# PIC32CX5112MTSH128S1 device description
Architecture: CORTEX-M4; Family: PIC32CXMT; Series: PIC32CXMTSH
Registers are 32-bit, read-write, no defined reset value unless marked. A register's access mark holds for its fields unless they carry their own. Offsets are from the block's base; [hi:lo] are bit positions; {n}, {i} and the like mark numbered series; <NAME> marks a mode.

## ADC — Analog-to-Digital Converter
Instances: ADC 0x40024000
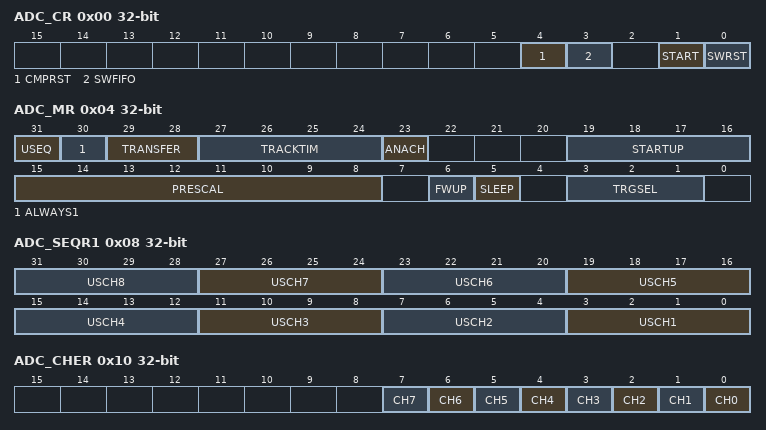
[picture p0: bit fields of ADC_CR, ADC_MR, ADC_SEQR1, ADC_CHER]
0x00 ADC_CR wo — Control Register
  [4] CMPRST — Comparison Restart
  [3] SWFIFO — Software FIFO Reset
  [1] START — Start Conversion
  [0] SWRST — Software Reset
0x04 ADC_MR — Mode Register
  [31] USEQ — User Sequence Enable
    0=NUM_ORDER (Normal mode: The controller converts channels in a simple numeric order depending only on the channel index.); 1=REG_ORDER (User Sequence mode: The sequence respects what is defined in ADC_SEQR1and can be used to convert the same channel several times.)
  [30] ALWAYS1
  [29:28] TRANSFER — Transfer Time
  [27:24] TRACKTIM — Tracking Time
  [23] ANACH — Analog Change
    0=NONE (No analog change on channel switching: DIFF0 is used for all channels.); 1=ALLOWED (Allows different analog settings for each channel. See ADC Channel Configuration Register.)
  [19:16] STARTUP — Startup Time
    0=SUT0 (0 period of ADCCLK); 1=SUT8 (8 periods of ADCCLK); 2=SUT16 (16 periods of ADCCLK); 3=SUT24 (24 periods of ADCCLK); 4=SUT64 (64 periods of ADCCLK); 5=SUT80 (80 periods of ADCCLK); 6=SUT96 (96 periods of ADCCLK); 7=SUT112 (112 periods of ADCCLK); 8=SUT512 (512 periods of ADCCLK); 9=SUT576 (576 periods of ADCCLK); 10=SUT640 (640 periods of ADCCLK); 11=SUT704 (704 periods of ADCCLK); 12=SUT768 (768 periods of ADCCLK); 13=SUT832 (832 periods of ADCCLK); 14=SUT896 (896 periods of ADCCLK); 15=SUT960 (960 periods of ADCCLK)
  [15:8] PRESCAL — Prescaler Rate Selection
  [6] FWUP — Fast Wake-up
    0=OFF (If SLEEP is 1, then both ADC core and reference voltage circuitry are off between conversions.); 1=ON (If SLEEP is 1, then Fast Wake-up Sleep mode: The voltage reference is on between conversions and ADC core is off.)
  [5] SLEEP — Sleep Mode
    0=NORMAL (Normal mode: The ADC core and reference voltage circuitry are kept on between conversions.); 1=SLEEP (Sleep mode: The wake-up time can be modified by programming the FWUP bit.)
  [3:1] TRGSEL — Trigger Selection
    0=ADC_TRIG0 (PWM event line 0); 1=ADC_TRIG1 (TIOA0 TC0); 2=ADC_TRIG2 (TIOA1 TC0); 3=ADC_TRIG3 (TIOA2 TC0); 4=ADC_TRIG4 (TIOA0 TC1); 5=ADC_TRIG5 (TIOA1 TC1); 6=ADC_TRIG6 (RTCOUT0)
0x08 ADC_SEQR1 — Channel Sequence Register 1
  [4n-1:4n-4] USCH{n} (n=1..8) — User Sequence Number {n}
0x10 ADC_CHER wo — Channel Enable Register
  [n] CH{n} (n=0..7) — Channel {n} Enable
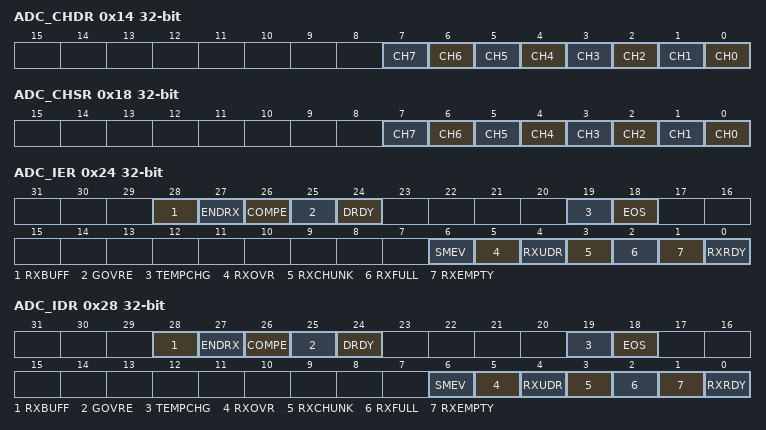
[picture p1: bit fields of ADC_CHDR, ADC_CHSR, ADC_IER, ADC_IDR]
0x14 ADC_CHDR wo — Channel Disable Register
  [n] CH{n} (n=0..7) — Channel {n} Disable
0x18 ADC_CHSR ro — Channel Status Register
  [n] CH{n} (n=0..7) — Channel {n} Status
0x20 ADC_LCDR ro — Last Converted Data Register
  [28:24] CHNBOSR <DEFAULT> — Channel Number in Oversampling Mode
  [15:0] LDATA <DEFAULT> — Last Data Converted
  [15:12] NO_OSR_CHNB <NO_OSR> — Channel Number when No Oversampling
  [11:0] NO_OSR_LDATA <NO_OSR> — Last Data Converted when No Oversampling
0x24 ADC_IER wo — Interrupt Enable Register
  [28] RXBUFF — Receive Buffer Full Interrupt Enable
  [27] ENDRX — End of Receive Transfer Interrupt Enable
  [26] COMPE — Comparison Event Interrupt Enable
  [25] GOVRE — General Overrun Error Interrupt Enable
  [24] DRDY — Data Ready Interrupt Enable
  [19] TEMPCHG — Temperature Change Interrupt Enable
  [18] EOS — End Of Sequence Interrupt Enable
  [6] SMEV — Supply Monitor Event Interrupt Enable
  [5] RXOVR — Receive Over Flow Interrupt Enable
  [4] RXUDR — Receive Under Flow Interrupt Enable
  [3] RXCHUNK — Receive FIFO Chunk Interrupt Enable
  [2] RXFULL — Receive FIFO Full Interrupt Enable
  [1] RXEMPTY — Receive FIFO Empty Interrupt Enable
  [0] RXRDY — Receive Ready Interrupt Enable
0x28 ADC_IDR wo — Interrupt Disable Register
  [28] RXBUFF — Receive Buffer Full Interrupt Disable
  [27] ENDRX — End of Receive Transfer Interrupt Disable
  [26] COMPE — Comparison Event Interrupt Disable
  [25] GOVRE — General Overrun Error Interrupt Disable
  [24] DRDY — Data Ready Interrupt Disable
  [19] TEMPCHG — Temperature Change Interrupt Disable
  [18] EOS — End Of Sequence Interrupt Disable
  [6] SMEV — Supply Monitor Event Interrupt Disable
  [5] RXOVR — Receive Over Flow Interrupt Disable
  [4] RXUDR — Receive Under Flow Interrupt Disable
  [3] RXCHUNK — Receive FIFO Chunk Interrupt Disable
  [2] RXFULL — Receive FIFO Full Interrupt Disable
  [1] RXEMPTY — Receive FIFO Empty Interrupt Disable
  [0] RXRDY — Receive Ready Interrupt Disable
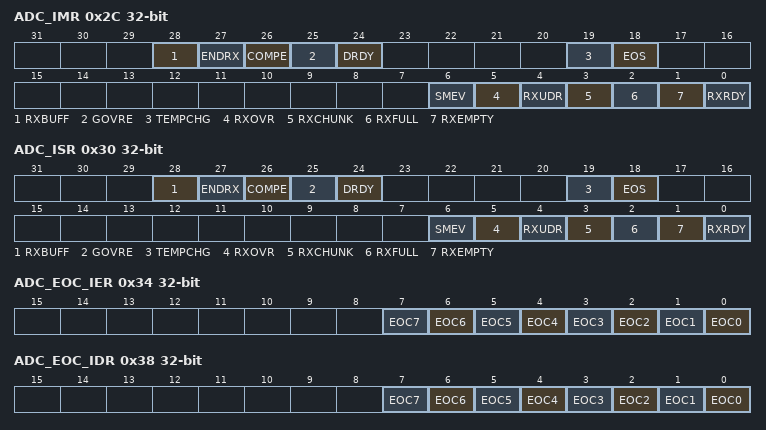
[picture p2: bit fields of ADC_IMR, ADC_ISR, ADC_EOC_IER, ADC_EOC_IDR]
0x2C ADC_IMR ro — Interrupt Mask Register
  [28] RXBUFF — Receive Buffer Full Interrupt Mask
  [27] ENDRX — End of Receive Transfer Interrupt Mask
  [26] COMPE — Comparison Event Interrupt Mask
  [25] GOVRE — General Overrun Error Interrupt Mask
  [24] DRDY — Data Ready Interrupt Mask
  [19] TEMPCHG — Temperature Change Interrupt Mask
  [18] EOS — End Of Sequence Interrupt Mask
  [6] SMEV — Supply Monitor Event Interrupt Mask
  [5] RXOVR — Receive Over Flow Interrupt Mask
  [4] RXUDR — Receive Under Flow Interrupt Mask
  [3] RXCHUNK — Receive FIFO Chunk Interrupt Mask
  [2] RXFULL — Receive FIFO Full Interrupt Mask
  [1] RXEMPTY — Receive FIFO Empty Interrupt Mask
  [0] RXRDY — Receive Ready Interrupt Mask
0x30 ADC_ISR ro — Interrupt Status Register
  [28] RXBUFF — Receive Buffer Full (cleared by writing ADC_RCR or ADC_RNCR)
  [27] ENDRX — End of Receive Transfer (cleared by writing ADC_RCR or ADC_RNCR)
  [26] COMPE — Comparison Event (cleared on read)
  [25] GOVRE — General Overrun Error (cleared on read)
  [24] DRDY — Data Ready (automatically set / cleared)
  [19] TEMPCHG — Temperature Change (cleared on read)
  [18] EOS — End Of Sequence (cleared on read)
  [6] SMEV — Supply Monitor Event (cleared on read)
  [5] RXOVR — Receive Over Flow (cleared on read)
  [4] RXUDR — Receive Under Flow (cleared on read)
  [3] RXCHUNK — Receive FIFO Chunk (cleared on read)
  [2] RXFULL — Receive FIFO Full (cleared on read)
  [1] RXEMPTY — Receive FIFO Empty (cleared on read)
  [0] RXRDY — Receive Ready (cleared on read)
0x34 ADC_EOC_IER wo — End Of Conversion Interrupt Enable Register
  [n] EOC{n} (n=0..7) — End of Conversion Interrupt Enable {n}
0x38 ADC_EOC_IDR wo — End Of Conversion Interrupt Disable Register
  [n] EOC{n} (n=0..7) — End of Conversion Interrupt Disable {n}
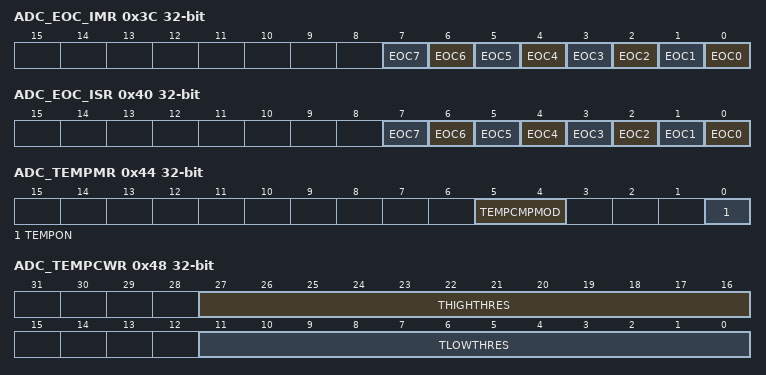
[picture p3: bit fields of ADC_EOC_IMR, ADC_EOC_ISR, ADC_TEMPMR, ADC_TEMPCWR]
0x3C ADC_EOC_IMR ro — End Of Conversion Interrupt Mask Register
  [n] EOC{n} (n=0..7) — End of Conversion Interrupt Mask {n}
0x40 ADC_EOC_ISR ro — End Of Conversion Interrupt Status Register
  [n] EOC{n} (n=0..7) — End of Conversion {n} (automatically set / cleared)
0x44 ADC_TEMPMR — Temperature Sensor Mode Register
  [5:4] TEMPCMPMOD — Temperature Comparison Mode
    0=LOW (Generates the TEMPCHG flag in ADC_ISR when the converted data is lower than the low threshold of the window.); 1=HIGH (Generates the TEMPCHG flag in ADC_ISR when the converted data is higher than the high threshold of the window.); 2=IN (Generates the TEMPCHG flag in ADC_ISR when the converted data is in the comparison window.); 3=OUT (Generates the TEMPCHG flag in ADC_ISR when the converted data is out of the comparison window.)
  [0] TEMPON — Temperature Sensor On
0x48 ADC_TEMPCWR — Temperature Compare Window Register
  [27:16] THIGHTHRES — Temperature High Threshold
  [11:0] TLOWTHRES — Temperature Low Threshold
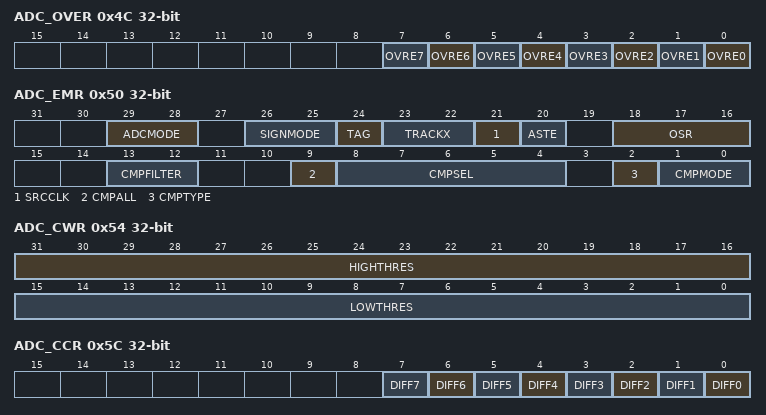
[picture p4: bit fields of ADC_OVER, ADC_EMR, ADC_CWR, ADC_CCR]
0x4C ADC_OVER ro — Overrun Status Register
  [n] OVRE{n} (n=0..7) — Overrun Error {n}
0x50 ADC_EMR — Extended Mode Register
  [29:28] ADCMODE — ADC Running Mode
    0=NORMAL (Normal mode of operation.); 1=OFFSET_ERROR (Offset Error mode to measure the offset error. See Table 6-6 "ADC Running Modes".); 2=GAIN_ERROR_HIGH (Gain Error mode to measure the gain error. See Table 6-6 "ADC Running Modes".); 3=GAIN_ERROR_LOW (Gain Error mode to measure the gain error. See Table 6-6 "ADC Running Modes".)
  [26:25] SIGNMODE
    0=SE_UNSG_DF_SIGN (Single-ended channels: unsigned conversions Differential channels: signed conversions); 1=SE_SIGN_DF_UNSG (Single-ended channels: signed conversions Differential channels: unsigned conversions); 2=ALL_UNSIGNED (All channels: unsigned conversions); 3=ALL_SIGNED (All channels: signed conversions)
  [24] TAG — ADC_LCDR Tag
  [23:22] TRACKX — Tracking Time x4, x8 or x16
    0=TRACKTIMX1 (ADC_MR.TRACKTIM effect is multiplied by 1.); 1=TRACKTIMX4 (ADC_MR.TRACKTIM effect is multiplied by 4.); 2=TRACKTIMX8 (ADC_MR.TRACKTIM effect is multiplied by 8); 3=TRACKTIMX16 (ADC_MR.TRACKTIM effect is multiplied by 16.)
  [21] SRCCLK — External Clock Selection
    0=PERIPH_CLK (The peripheral clock is the source for the ADC prescaler.); 1=GCLK (GCLK is the source clock for the ADC prescaler, thus the ADC clock can be independent of the core/peripheral clock.)
  [20] ASTE — Averaging on Single Trigger Event
    0=MULTI_TRIG_AVERAGE (The average requests several trigger events.); 1=SINGLE_TRIG_AVERAGE (The average requests only one trigger event.)
  [18:16] OSR — Over Sampling Rate
    0=NO_AVERAGE (No averaging. ADC sample rate is maximum.); 1=1-bit enhanced resolution by averaging. ADC sample rate divided by 4.; 2=2-bit enhanced resolution by averaging. ADC sample rate divided by 16.; 3=1-bit enhanced resolution by averaging. ADC sample rate divided by 64; 4=2-bit enhanced resolution by averaging. ADC sample rate divided by 256.
  [13:12] CMPFILTER — Compare Event Filtering
  [9] CMPALL — Compare All Channels
  [8:4] CMPSEL — Comparison Selected Channel
  [2] CMPTYPE — Comparison Type
    0=FLAG_ONLY (Any conversion is performed and comparison function drives the COMPE flag.); 1=START_CONDITION (Comparison conditions must be met to start the storage of all conversions until ADC_CR.CMPRST is set.)
  [1:0] CMPMODE — Comparison Mode
    0=LOW (When the converted data is lower than the low threshold of the window, generates the COMPE flag in ADC_ISR or, in Partial Wake-up mode, defines the conditions to exit the system from Wait mode.); 1=HIGH (When the converted data is higher than the high threshold of the window, generates the COMPE flag in ADC_ISR or, in Partial Wake-up mode, defines the conditions to exit the system from Wait mode.); 2=IN (When the converted data is in the comparison window, generates the COMPE flag in ADC_ISR or, in Partial Wake-up mode, defines the conditions to exit the system from Wait mode.); 3=OUT (When the converted data is out of the comparison window, generates the COMPE flag in ADC_ISR or, in Partial Wake-up mode, defines the conditions to exit the system from Wait mode.)
0x54 ADC_CWR — Compare Window Register
  [31:16] HIGHTHRES — High Threshold
  [15:0] LOWTHRES — Low Threshold
0x5C ADC_CCR — Channel Configuration Register
  [n] DIFF{n} (n=0..7) — Differential Inputs for Channel {n}
{0x60+4i} ADC_CDR[{i}] (i=0..7) ro — Channel Data Register
  [15:0] DATA — Converted Data
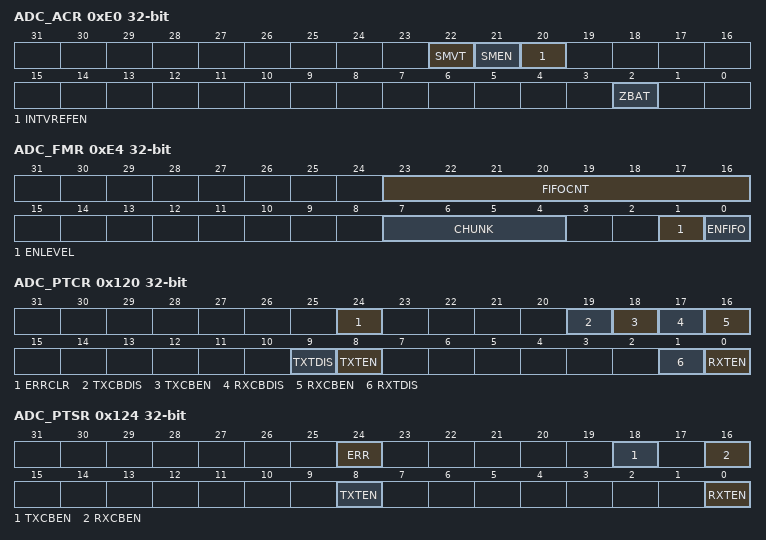
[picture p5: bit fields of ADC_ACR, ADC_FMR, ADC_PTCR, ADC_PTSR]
0xE0 ADC_ACR — Analog Control Register
  [22] SMVT — Supply Monitor Voltage Threshold
  [21] SMEN — Supply Monitor Enable
  [20] INTVREFEN — ADC Internal Positive Voltage Reference Enable
  [2] ZBAT — VBAT Resistive Load Selection
0xE4 ADC_FMR — FIFO Mode Register
  [23:16] FIFOCNT — FIFO Count (read-only)
  [7:4] CHUNK — Chunk Size
  [1] ENLEVEL — Enable Level
    0=Request to DMA is generated as soon as one data is written in FIFO when FIFO is enabled. CHUNK is not used.; 1=Request to DMA is generated as soon as the number of written elements in the FIFO is greater than or equal to CHUNK
  [0] ENFIFO — Enable FIFO
    0=FIFO is disabled; 1=FIFO is enabled
0x100 ADC_RPR — Receive Pointer Register
  [31:0] RXPTR
0x104 ADC_RCR — Receive Counter Register
  [15:0] RXCTR
0x110 ADC_RNPR — Receive Next Pointer Register
  [31:0] RXNPTR — Receive Next Pointer
0x114 ADC_RNCR — Receive Next Counter Register
  [15:0] RXNCTR — Receive Next Counter
0x120 ADC_PTCR wo — Transfer Control Register
  [24] ERRCLR — Transfer Bus Error Clear
  [19] TXCBDIS — Transmitter Circular Buffer Disable
  [18] TXCBEN — Transmitter Circular Buffer Enable
  [17] RXCBDIS — Receiver Circular Buffer Disable
  [16] RXCBEN — Receiver Circular Buffer Enable
  [9] TXTDIS — Transmitter Transfer Disable
  [8] TXTEN — Transmitter Transfer Enable
  [1] RXTDIS — Receiver Transfer Disable
  [0] RXTEN — Receiver Transfer Enable
0x124 ADC_PTSR ro — Transfer Status Register
  [24] ERR — Transfer Bus Error
  [18] TXCBEN — Transmitter Circular Buffer Enable
  [16] RXCBEN — Receiver Circular Buffer Enable
  [8] TXTEN — Transmitter Transfer Enable
  [0] RXTEN — Receiver Transfer Enable
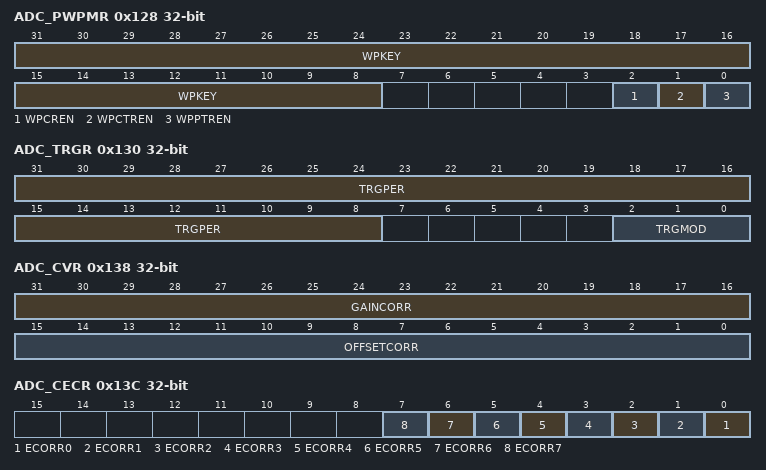
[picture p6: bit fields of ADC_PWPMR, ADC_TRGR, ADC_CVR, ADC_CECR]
0x128 ADC_PWPMR — Write Protection Mode Register
  [31:8] WPKEY — Write Protection Key
    0x504443=PASSWD (Writing any other value in this field aborts the write operation. Always reads as 0.)
  [2] WPCREN — Write Protection Control Register Enable
  [1] WPCTREN — Write Protection Counter Registers Enable
  [0] WPPTREN — Write Protection Pointer Registers Enable
0x130 ADC_TRGR — Trigger Register
  [31:8] TRGPER — Trigger Period
  [2:0] TRGMOD — Trigger Mode
    0=NO_TRIGGER (No hardware trigger, only software trigger can start conversions); 1=EXT_TRIG_RISE (Rising edge of the selected trigger event, defined in ADC_MR.TRGSEL); 2=EXT_TRIG_FALL (Falling edge of the selected trigger event); 3=EXT_TRIG_ANY (Any edge of the selected trigger event); 5=PERIOD_TRIG (ADC internal periodic trigger (see TRGPER)); 6=CONTINUOUS (Continuous mode, free run mode)
0x134 ADC_COSR — Correction Select Register
  [4:0] CSEL — Channel Correction Select
0x138 ADC_CVR — Correction Values Register
  [31:16] GAINCORR — Gain Correction
  [15:0] OFFSETCORR — Offset Correction
0x13C ADC_CECR — Channel Error Correction Register
  [n] ECORR{n} (n=0..7) — Error Correction Enable for Channel {n}
0x144 ADC_SR ro — Status Register
  [0] VADCSM — VDD ADC Supply Monitor Output
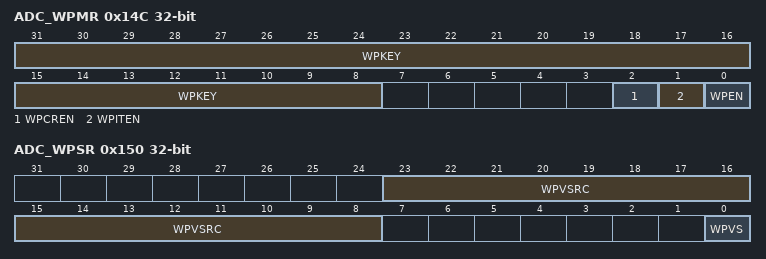
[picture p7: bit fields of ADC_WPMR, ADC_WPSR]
0x14C ADC_WPMR — Write Protection Mode Register
  [31:8] WPKEY — Write Protection Key
    0x414443=PASSWD (Writing any other value in this field aborts the write operation of the WPEN bit. Always reads as 0.)
  [2] WPCREN — Write Protection Control Register Enable
  [1] WPITEN — Write Protection Interrupt Enable
  [0] WPEN — Write Protection Enable
0x150 ADC_WPSR ro — Write Protection Status Register
  [23:8] WPVSRC — Write Protection Violation Source
  [0] WPVS — Write Protection Violation Status

## Notices in the file
Copyright %copyright_year% Microchip Technology Inc.
SPDX-License-Identifier: Apache-2.0
Licensed under the Apache License, Version 2.0 (the "License");
you may not use this file except in compliance with the License.
You may obtain a copy of the License at
http://www.apache.org/licenses/LICENSE-2.0
Unless required by applicable law or agreed to in writing, software
distributed under the License is distributed on an "AS IS" BASIS,
WITHOUT WARRANTIES OR CONDITIONS OF ANY KIND, either express or implied.
See the License for the specific language governing permissions and
limitations under the License.
